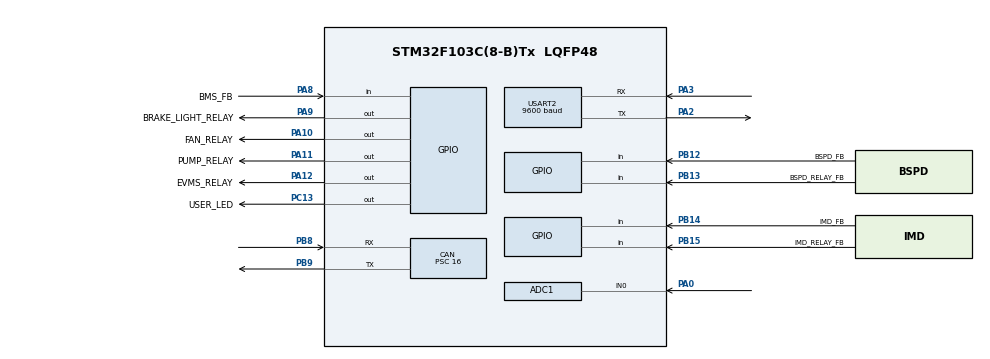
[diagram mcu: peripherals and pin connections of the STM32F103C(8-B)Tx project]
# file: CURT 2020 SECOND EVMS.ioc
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ADC1.NbrOfConversionFlag=1
ADC1.master=1
CAN.BS1=CAN_BS1_12TQ
CAN.BS2=CAN_BS2_5TQ
CAN.CalculateTimeBit=7999.99
CAN.CalculateTimeQuantum=444.44444444444446
CAN.Prescaler=16
Mcu.Family=STM32F1
Mcu.Name=STM32F103C(8-B)Tx
Mcu.Package=LQFP48
NVIC.PriorityGroup=NVIC_PRIORITYGROUP_4
PA0-WKUP.GPIO_Mode=GPIO_MODE_ANALOG
PA0-WKUP.Signal=ADCx_IN0
PA1.GPIO_Label=BRAKES_PRESSURE
PA1.Signal=ADCx_IN1
PA10.GPIO_Label=FAN_RELAY
PA10.Signal=GPIO_Output
PA11.GPIO_Label=PUMP_RELAY
PA11.Signal=GPIO_Output
PA12.GPIO_Label=EVMS_RELAY
PA12.Signal=GPIO_Output
PA2.Mode=Asynchronous
PA2.Signal=USART2_TX
PA3.Mode=Asynchronous
PA3.Signal=USART2_RX
PA8.GPIO_Label=BMS_FB
PA8.Signal=GPIO_Input
PA9.GPIO_Label=BRAKE_LIGHT_RELAY
PA9.Signal=GPIO_Output
PB12.GPIO_Label=BSPD_FB
PB12.Signal=GPIO_Input
PB13.GPIO_Label=BSPD_RELAY_FB
PB13.Signal=GPIO_Input
PB14.GPIO_Label=IMD_FB
PB14.Signal=GPIO_Input
PB15.GPIO_Label=IMD_RELAY_FB
PB15.Signal=GPIO_Input
PB8.Mode=Master
PB8.Signal=CAN_RX
PB9.Mode=Master
PB9.Signal=CAN_TX
PC13-TAMPER-RTC.GPIO_Label=USER_LED
PC13-TAMPER-RTC.PinState=GPIO_PIN_SET
PC13-TAMPER-RTC.Signal=GPIO_Output
PC14-OSC32_IN.Mode=LSE-External-Oscillator
PC14-OSC32_IN.Signal=RCC_OSC32_IN
PC15-OSC32_OUT.Mode=LSE-External-Oscillator
PC15-OSC32_OUT.Signal=RCC_OSC32_OUT
PD0-OSC_IN.Mode=HSE-External-Oscillator
PD0-OSC_IN.Signal=RCC_OSC_IN
PD1-OSC_OUT.Mode=HSE-External-Oscillator
PD1-OSC_OUT.Signal=RCC_OSC_OUT
ProjectManager.HeapSize=0x200
ProjectManager.StackSize=0x400
ProjectManager.TargetToolchain=TrueSTUDIO
RCC.ADCPresc=RCC_ADCPCLK2_DIV8
RCC.AHBFreq_Value=72000000
RCC.APB1CLKDivider=RCC_HCLK_DIV2
RCC.APB1Freq_Value=36000000
RCC.APB1TimFreq_Value=72000000
RCC.APB2CLKDivider=RCC_HCLK_DIV8
RCC.APB2Freq_Value=9000000
RCC.APB2TimFreq_Value=18000000
RCC.HCLKFreq_Value=72000000
RCC.PLLMUL=RCC_PLL_MUL9
RCC.PLLSourceVirtual=RCC_PLLSOURCE_HSE
RCC.SYSCLKFreq_VALUE=72000000
RCC.SYSCLKSource=RCC_SYSCLKSOURCE_PLLCLK
RCC.USBFreq_Value=72000000
SH.ADCx_IN0.0=ADC1_IN0,IN0
SH.ADCx_IN1.0=ADC1_IN1
USART2.BaudRate=9600
USART2.VirtualMode=VM_ASYNC
VP_SYS_VS_ND.Mode=No_Debug
board=custom

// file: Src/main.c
/* USER CODE BEGIN Header */
/**
 ******************************************************************************
 * @file           : main.c
 * @brief          : Main program body
 ******************************************************************************
 * @attention
 *
 * <h2><center>&copy; Copyright (c) 2023 STMicroelectronics.
 * All rights reserved.</center></h2>
 *
 * This software component is licensed by ST under BSD 3-Clause license,
 * the "License"; You may not use this file except in compliance with the
 * License. You may obtain a copy of the License at:
 *                        opensource.org/licenses/BSD-3-Clause
 *
 ******************************************************************************
 */
/* USER CODE END Header */

#include "main.h"
#include "../BluePill Drivers/CURT_CAN/CURT_CAN_headers/CAN_interface.h"

/* USER CODE BEGIN Includes */
#include "EVMS2.h"
/* USER CODE END Includes */

ADC_HandleTypeDef hadc1;

CAN_HandleTypeDef hcan;

UART_HandleTypeDef huart2;

void SystemClock_Config(void);
static void MX_GPIO_Init(void);
static void MX_ADC1_Init(void);
static void MX_USART2_UART_Init(void);
static void MX_CAN_Init(void);

int main(void) {

	/* MCU Configuration--------------------------------------------------------*/

	/* Reset of all peripherals, Initializes the Flash interface and the Systick. */
	HAL_Init();

	/* Configure the system clock */
	SystemClock_Config();

	/* Initialize all configured peripherals */
	MX_GPIO_Init();
	MX_ADC1_Init();
	MX_USART2_UART_Init();
	MX_CAN_Init();
	/* USER CODE BEGIN 2 */
	HAL_ADCEx_Calibration_Start(&hadc1);
	/* USER CODE END 2 */

	/* Infinite loop */
	/* USER CODE BEGIN WHILE */
	HAL_CAN_Start(&hcan);
	CAN_RxHeaderTypeDef header = { 0 };
	unsigned char rx_data[8] = { 0 };
	//CAN_FilterTypeDef config_filter = {0, 0, 0, 0, CAN_RX_FIFO0, 0, CAN_FILTERMODE_IDMASK, CAN_FILTERSCALE_32BIT, ENABLE, 14};
	CAN_appendDeviceToBus(0x6AC, CAN_STANDARD_IDENTIFIER);
	unsigned char received_len = 0;
	//HAL_CAN_ConfigFilter(&hcan, &config_filter);
	while (1) {
		//HAL_GPIO_WritePin(GPIOC,USER_LED_Pin,GPIO_PIN_RESET);
//		if (HAL_CAN_GetRxMessage(&hcan, CAN_RX_FIFO0, &header, rx_data)
//				== HAL_OK) {
		if (CAN_receiveMessage(rx_data, &received_len, 0x6ac) == CAN_Status_OK)
//			int x = 23;
//			int y = 45;
			HAL_GPIO_WritePin(GPIOC, USER_LED_Pin, GPIO_PIN_RESET);
	}

	/* USER CODE END WHILE */

	/* USER CODE BEGIN 3 */
//		EVMS2_init();
//		LOGIC_voidControlBrakeLight();
//		LOGIC_voidControlFan();
//		LOGIC_voidControlPump();
//
//		if (isError() == ERROR) {
//			Error_Action();
//		} //end if
//		else {
//			//HAL_GPIO_WritePin(BRAKE_LIGHT_RELAY_GPIO_Port,BRAKE_LIGHT_RELAY_Pin,0);
//		} //end else
//}
/* USER CODE END 3 */
}

void SystemClock_Config(void) {
RCC_OscInitTypeDef RCC_OscInitStruct = { 0 };
RCC_ClkInitTypeDef RCC_ClkInitStruct = { 0 };
RCC_PeriphCLKInitTypeDef PeriphClkInit = { 0 };

/** Initializes the CPU, AHB and APB busses clocks
 */
RCC_OscInitStruct.OscillatorType = RCC_OSCILLATORTYPE_HSE;
RCC_OscInitStruct.HSEState = RCC_HSE_ON;
RCC_OscInitStruct.HSEPredivValue = RCC_HSE_PREDIV_DIV1;
RCC_OscInitStruct.HSIState = RCC_HSI_ON;
RCC_OscInitStruct.PLL.PLLState = RCC_PLL_ON;
RCC_OscInitStruct.PLL.PLLSource = RCC_PLLSOURCE_HSE;
RCC_OscInitStruct.PLL.PLLMUL = RCC_PLL_MUL9;
if (HAL_RCC_OscConfig(&RCC_OscInitStruct) != HAL_OK) {
	Error_Handler();
}
/** Initializes the CPU, AHB and APB busses clocks
 */
RCC_ClkInitStruct.ClockType = RCC_CLOCKTYPE_HCLK | RCC_CLOCKTYPE_SYSCLK
		| RCC_CLOCKTYPE_PCLK1 | RCC_CLOCKTYPE_PCLK2;
RCC_ClkInitStruct.SYSCLKSource = RCC_SYSCLKSOURCE_PLLCLK;
RCC_ClkInitStruct.AHBCLKDivider = RCC_SYSCLK_DIV1;
RCC_ClkInitStruct.APB1CLKDivider = RCC_HCLK_DIV2;
RCC_ClkInitStruct.APB2CLKDivider = RCC_HCLK_DIV8;

if (HAL_RCC_ClockConfig(&RCC_ClkInitStruct, FLASH_LATENCY_2) != HAL_OK) {
	Error_Handler();
}
PeriphClkInit.PeriphClockSelection = RCC_PERIPHCLK_ADC;
PeriphClkInit.AdcClockSelection = RCC_ADCPCLK2_DIV8;
if (HAL_RCCEx_PeriphCLKConfig(&PeriphClkInit) != HAL_OK) {
	Error_Handler();
}
}

static void MX_ADC1_Init(void) {

/** Common config
 */
hadc1.Instance = ADC1;
hadc1.Init.ScanConvMode = ADC_SCAN_DISABLE;
hadc1.Init.ContinuousConvMode = DISABLE;
hadc1.Init.DiscontinuousConvMode = DISABLE;
hadc1.Init.ExternalTrigConv = ADC_SOFTWARE_START;
hadc1.Init.DataAlign = ADC_DATAALIGN_RIGHT;
hadc1.Init.NbrOfConversion = 1;
if (HAL_ADC_Init(&hadc1) != HAL_OK) {
	Error_Handler();
}

}

static void MX_CAN_Init(void) {

hcan.Instance = CAN1;
hcan.Init.Prescaler = 16;
hcan.Init.Mode = CAN_MODE_NORMAL;
hcan.Init.SyncJumpWidth = CAN_SJW_1TQ;
hcan.Init.TimeSeg1 = CAN_BS1_12TQ;
hcan.Init.TimeSeg2 = CAN_BS2_5TQ;
hcan.Init.TimeTriggeredMode = DISABLE;
hcan.Init.AutoBusOff = DISABLE;
hcan.Init.AutoWakeUp = DISABLE;
hcan.Init.AutoRetransmission = DISABLE;
hcan.Init.ReceiveFifoLocked = DISABLE;
hcan.Init.TransmitFifoPriority = DISABLE;
if (HAL_CAN_Init(&hcan) != HAL_OK) {
	Error_Handler();
}

}

static void MX_USART2_UART_Init(void) {

huart2.Instance = USART2;
huart2.Init.BaudRate = 9600;
huart2.Init.WordLength = UART_WORDLENGTH_8B;
huart2.Init.StopBits = UART_STOPBITS_1;
huart2.Init.Parity = UART_PARITY_NONE;
huart2.Init.Mode = UART_MODE_TX_RX;
huart2.Init.HwFlowCtl = UART_HWCONTROL_NONE;
huart2.Init.OverSampling = UART_OVERSAMPLING_16;
if (HAL_UART_Init(&huart2) != HAL_OK) {
	Error_Handler();
}

}

static void MX_GPIO_Init(void) {
GPIO_InitTypeDef GPIO_InitStruct = { 0 };

/* GPIO Ports Clock Enable */
__HAL_RCC_GPIOC_CLK_ENABLE()
;
__HAL_RCC_GPIOD_CLK_ENABLE()
;
__HAL_RCC_GPIOA_CLK_ENABLE()
;
__HAL_RCC_GPIOB_CLK_ENABLE()
;

/*Configure GPIO pin Output Level */
HAL_GPIO_WritePin(USER_LED_GPIO_Port, USER_LED_Pin, GPIO_PIN_SET);

/*Configure GPIO pin Output Level */
HAL_GPIO_WritePin(GPIOA,
		BRAKE_LIGHT_RELAY_Pin | FAN_RELAY_Pin | PUMP_RELAY_Pin | EVMS_RELAY_Pin,
		GPIO_PIN_RESET);

/*Configure GPIO pin : USER_LED_Pin */
GPIO_InitStruct.Pin = USER_LED_Pin;
GPIO_InitStruct.Mode = GPIO_MODE_OUTPUT_PP;
GPIO_InitStruct.Pull = GPIO_NOPULL;
GPIO_InitStruct.Speed = GPIO_SPEED_FREQ_LOW;
HAL_GPIO_Init(USER_LED_GPIO_Port, &GPIO_InitStruct);

/*Configure GPIO pins : BSPD_FB_Pin BSPD_RELAY_FB_Pin IMD_FB_Pin IMD_RELAY_FB_Pin */
GPIO_InitStruct.Pin = BSPD_FB_Pin | BSPD_RELAY_FB_Pin | IMD_FB_Pin
		| IMD_RELAY_FB_Pin;
GPIO_InitStruct.Mode = GPIO_MODE_INPUT;
GPIO_InitStruct.Pull = GPIO_NOPULL;
HAL_GPIO_Init(GPIOB, &GPIO_InitStruct);

/*Configure GPIO pin : BMS_FB_Pin */
GPIO_InitStruct.Pin = BMS_FB_Pin;
GPIO_InitStruct.Mode = GPIO_MODE_INPUT;
GPIO_InitStruct.Pull = GPIO_NOPULL;
HAL_GPIO_Init(BMS_FB_GPIO_Port, &GPIO_InitStruct);

/*Configure GPIO pins : BRAKE_LIGHT_RELAY_Pin FAN_RELAY_Pin PUMP_RELAY_Pin EVMS_RELAY_Pin */
GPIO_InitStruct.Pin = BRAKE_LIGHT_RELAY_Pin | FAN_RELAY_Pin | PUMP_RELAY_Pin
		| EVMS_RELAY_Pin;
GPIO_InitStruct.Mode = GPIO_MODE_OUTPUT_PP;
GPIO_InitStruct.Pull = GPIO_NOPULL;
GPIO_InitStruct.Speed = GPIO_SPEED_FREQ_LOW;
HAL_GPIO_Init(GPIOA, &GPIO_InitStruct);

}

void Error_Handler(void) {
}

/************************ (C) COPYRIGHT STMicroelectronics *****END OF FILE****/
